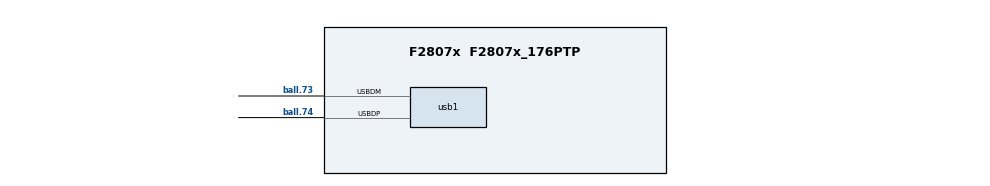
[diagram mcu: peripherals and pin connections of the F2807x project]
/**
 * @cliArgs --device "F2807x" --part "F2807x_176PTP" --package "F2807x_176PTP" --context "system"
 */


/**
 * Import the modules used in this configuration.
 */
const usb  = scripting.addModule("/driverlib/usb.js", {}, false);
const usb1 = usb.addInstance();

/**
 * Write custom configuration values to the imported modules.
 */
usb1.$name                   = "myUSB0";
usb1.registerInterrupts      = true;
usb1.usb.$assign             = "USB0";
usb1.usb.usbdmPin.$assign    = "ball.73";
usb1.usb.usbdpPin.$assign    = "ball.74";
usb1.usbLib.usb_mode         = "Dual";
usb1.usbLib.deviceClasses    = "Mouse";
usb1.dmQual.$name            = "myGPIOQUAL0";
usb1.dpQual.$name            = "myGPIOQUAL1";
usb1.USBInt.enableInterrupt  = true;
usb1.USBInt.interruptHandler = "f28x_USB0DualModeIntHandler";
